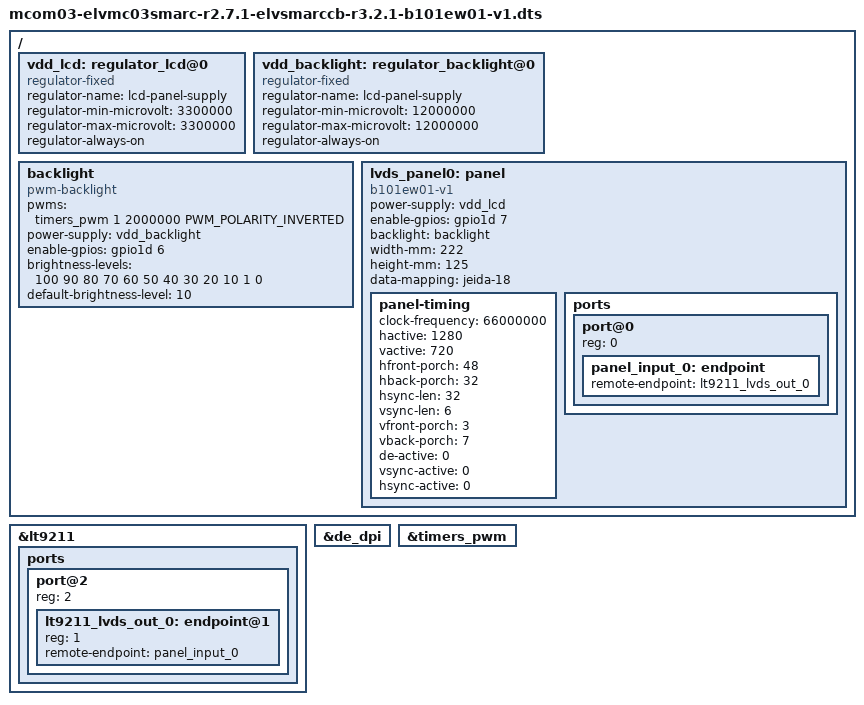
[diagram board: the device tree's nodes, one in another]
// SPDX-License-Identifier: GPL-2.0+
/*
 * Copyright 2024 RnD Center "ELVEES", JSC
 */

#include "mcom03-elvmc03smarc-r2.7.1-elvsmarccb-r3.2.1.dts"
#include <dt-bindings/pwm/pwm.h>

/ {
	vdd_lcd: regulator_lcd@0 {
		compatible = "regulator-fixed";
		regulator-name = "lcd-panel-supply";
		regulator-min-microvolt = <3300000>;
		regulator-max-microvolt = <3300000>;
		regulator-always-on;
	};

	vdd_backlight: regulator_backlight@0 {
		compatible = "regulator-fixed";
		regulator-name = "lcd-panel-supply";
		regulator-min-microvolt = <12000000>;
		regulator-max-microvolt = <12000000>;
		regulator-always-on;
	};

	backlight: backlight {
		compatible = "pwm-backlight";

		pwms = <&timers_pwm 1 2000000 PWM_POLARITY_INVERTED>;
		power-supply = <&vdd_backlight>;
		enable-gpios = <&gpio1d 6 GPIO_ACTIVE_HIGH>;

		brightness-levels = <100 90 80 70 60 50 40 30 20 10 1 0>;
		default-brightness-level = <10>;
	};

	lvds_panel0: panel {
		compatible = "b101ew01-v1", "panel-lvds";

		power-supply = <&vdd_lcd>;

		enable-gpios = <&gpio1d 7 GPIO_ACTIVE_HIGH>;
		backlight = <&backlight>;

		width-mm = <222>;
		height-mm = <125>;

		data-mapping = "jeida-18";

		panel-timing {
			clock-frequency = <66000000>;
			hactive = <1280>;
			vactive = <720>;
			// TODO: Reacalc to 1375 x 800 total resolution for 60 Hz refresh rate
			hfront-porch = <48>;
			hback-porch = <32>;
			hsync-len = <32>;
			vsync-len = <6>;
			vfront-porch = <3>;
			vback-porch = <7>;

			de-active = <0>;
			vsync-active = <0>;
			hsync-active = <0>;
		};

		ports {
			#address-cells = <1>;
			#size-cells = <0>;

			port@0 {
				reg = <0>;

				panel_input_0: endpoint {
					remote-endpoint = <&lt9211_lvds_out_0>;
				};
			};
		};
	};
};

&lt9211 {
	status = "okay";

	ports {
		// lvds-out
		port@2 {
			#address-cells = <1>;
			#size-cells = <0>;
			reg = <2>;

			lt9211_lvds_out_0: endpoint@1 {
				reg = <1>;
				remote-endpoint = <&panel_input_0>;
			};
		};
	};
};

&de_dpi {
	status = "okay";
};

&timers_pwm {
	status = "okay";
};
